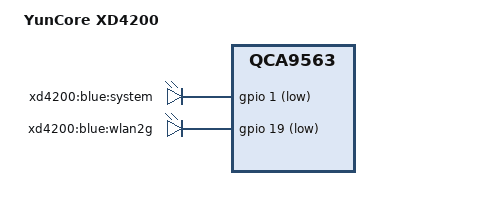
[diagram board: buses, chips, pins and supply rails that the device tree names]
// SPDX-License-Identifier: GPL-2.0-or-later OR MIT

#include "qca9563_yuncore_xd4200.dtsi"

/ {
	compatible = "yuncore,xd4200", "qca,qca9563";
	model = "YunCore XD4200";

	aliases {
		led-boot = &led_system;
		led-failsafe = &led_system;
		led-running = &led_system;
		led-upgrade = &led_system;
	};

	leds {
		compatible = "gpio-leds";

		led_system: system {
			label = "xd4200:blue:system";
			gpios = <&gpio 1 GPIO_ACTIVE_LOW>;
			default-state = "keep";
		};

		wlan2g {
			label = "xd4200:blue:wlan2g";
			gpios = <&gpio 19 GPIO_ACTIVE_LOW>;
			linux,default-trigger = "phy1tpt";
		};
	};
};
